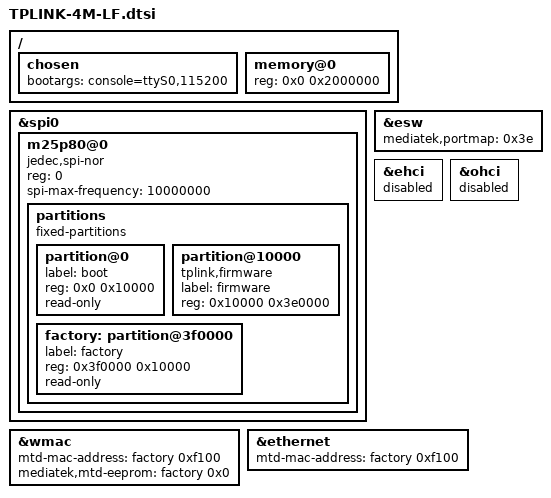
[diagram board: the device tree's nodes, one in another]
#include "mt7628an.dtsi"

/ {
	chosen {
		bootargs = "console=ttyS0,115200";
	};

	memory@0 {
		device_type = "memory";
		reg = <0x0 0x2000000>;
	};
};

&spi0 {
	status = "okay";

	m25p80@0 {
		compatible = "jedec,spi-nor";
		reg = <0>;
		spi-max-frequency = <10000000>;

		partitions {
			compatible = "fixed-partitions";
			#address-cells = <1>;
			#size-cells = <1>;

			partition@0 {
				label = "boot";
				reg = <0x0 0x10000>;
				read-only;
			};

			partition@10000 {
				compatible = "tplink,firmware";
				label = "firmware";
				reg = <0x10000 0x3e0000>;
			};

			factory: partition@3f0000 {
				label = "factory";
				reg = <0x3f0000 0x10000>;
				read-only;
			};
		};
	};
};

&esw {
	mediatek,portmap = <0x3e>;
};

&ehci {
	status = "disabled";
};

&ohci {
	status = "disabled";
};

&wmac {
	status = "okay";
	mtd-mac-address = <&factory 0xf100>;
	mediatek,mtd-eeprom = <&factory 0x0>;
};

&ethernet {
	mtd-mac-address = <&factory 0xf100>;
};
